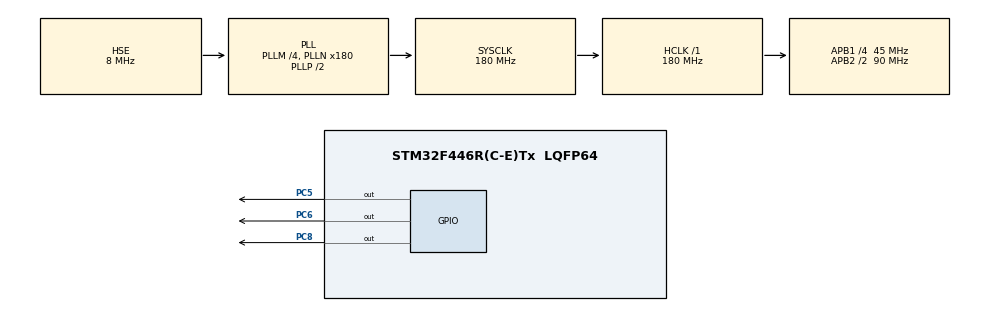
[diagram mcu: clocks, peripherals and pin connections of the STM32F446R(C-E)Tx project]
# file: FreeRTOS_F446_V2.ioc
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Mcu.Family=STM32F4
Mcu.Name=STM32F446R(C-E)Tx
Mcu.Package=LQFP64
NVIC.PriorityGroup=NVIC_PRIORITYGROUP_4
NVIC.TIM8_TRG_COM_TIM14_IRQn=true\:5\:0\:true\:false\:true\:false\:true\:true
NVIC.TimeBase=TIM8_TRG_COM_TIM14_IRQn
NVIC.TimeBaseIP=TIM14
PA13.Mode=Trace_Asynchronous_SW
PA13.Signal=SYS_JTMS-SWDIO
PA14.Mode=Trace_Asynchronous_SW
PA14.Signal=SYS_JTCK-SWCLK
PB3.Mode=Trace_Asynchronous_SW
PB3.Signal=SYS_JTDO-SWO
PC5.Signal=GPIO_Output
PC6.Signal=GPIO_Output
PC8.Signal=GPIO_Output
PH0-OSC_IN.Mode=HSE-External-Clock-Source
PH0-OSC_IN.Signal=RCC_OSC_IN
PH1-OSC_OUT.Mode=HSE-External-Clock-Source
PH1-OSC_OUT.Signal=RCC_OSC_OUT
ProjectManager.HeapSize=0x200
ProjectManager.StackSize=0x400
ProjectManager.TargetToolchain=STM32CubeIDE
RCC.AHBFreq_Value=180000000
RCC.APB1CLKDivider=RCC_HCLK_DIV4
RCC.APB1Freq_Value=45000000
RCC.APB1TimFreq_Value=90000000
RCC.APB2CLKDivider=RCC_HCLK_DIV2
RCC.APB2Freq_Value=90000000
RCC.APB2TimFreq_Value=180000000
RCC.CortexFreq_Value=180000000
RCC.HCLKFreq_Value=180000000
RCC.HSE_VALUE=8000000
RCC.PLLM=4
RCC.PLLN=180
RCC.PLLSourceVirtual=RCC_PLLSOURCE_HSE
RCC.SYSCLKFreq_VALUE=180000000
RCC.SYSCLKSource=RCC_SYSCLKSOURCE_PLLCLK
RCC.USBFreq_Value=180000000
RCC.VCOOutputFreq_Value=360000000
VP_SYS_VS_tim14.Mode=TIM14
board=custom

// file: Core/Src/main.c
/* USER CODE BEGIN Header */
/**
  ******************************************************************************
  * @file           : main.c
  * @brief          : Main program body
  ******************************************************************************
  * @attention
  *
  * Copyright (c) 2025 STMicroelectronics.
  * All rights reserved.
  *
  * This software is licensed under terms that can be found in the LICENSE file
  * in the root directory of this software component.
  * If no LICENSE file comes with this software, it is provided AS-IS.
  *
  ******************************************************************************
  */
/* USER CODE END Header */
#include "main.h"

/* USER CODE BEGIN Includes */
#include"FreeRTOS.h"
#include"task.h"
#include <stdbool.h>

/* USER CODE END Includes */

/* USER CODE BEGIN PD */
#define DWT_CTRL    (*(volatile uint32_t*)0xE0001000)
/* USER CODE END PD */

/* USER CODE BEGIN PV */

TaskHandle_t Task1Handle = NULL;
TaskHandle_t Task2Handle = NULL;
TaskHandle_t Task3Handle = NULL;
TaskHandle_t ButtonTaskHandle = NULL;

TaskHandle_t NumberDeleteTask = NULL;

/* USER CODE END PV */

void SystemClock_Config(void);
static void MX_GPIO_Init(void);

/* USER CODE BEGIN 0 */

extern  void SEGGER_UART_init(uint32_t);

void vTaskCode1( void * pvParameters )
{
	( void ) pvParameters;

	BaseType_t status;

	for( ;; )
	{
		HAL_GPIO_TogglePin(GPIOC, GPIO_PIN_5);
		status = xTaskNotifyWait(0,0,NULL,pdMS_TO_TICKS(200));
		if(status == pdPASS)
		{
			NumberDeleteTask = Task2Handle;
			vTaskDelete(Task1Handle);
		}

	}
}

void vTaskCode2( void * pvParameters )
{
	( void ) pvParameters;

	BaseType_t status;

	for( ;; )
	{
		HAL_GPIO_TogglePin(GPIOC, GPIO_PIN_6);
		status = xTaskNotifyWait(0,0,NULL,pdMS_TO_TICKS(400));
		if(status == pdPASS)
		{
			NumberDeleteTask = Task3Handle;
			vTaskDelete(Task2Handle);
		}
	}
}

void vTaskCode3( void * pvParameters )
{
	( void ) pvParameters;

	BaseType_t status;

	for( ;; )
	{

		HAL_GPIO_TogglePin(GPIOC, GPIO_PIN_8);
		status = xTaskNotifyWait(0,0,NULL,pdMS_TO_TICKS(800));
		if(status == pdPASS)
		{
			vTaskDelete(Task3Handle);
		}
	}
}

void ButtonTask( void * pvParameters )
{
	( void ) pvParameters;
	bool state = 0;
	bool prev_red = 0;
	NumberDeleteTask = Task1Handle;

	for( ;; )
	{
		state = HAL_GPIO_ReadPin(GPIOC, GPIO_PIN_13);
		if(!state)
		{
			if(prev_red)
			{
				xTaskNotify(NumberDeleteTask, 0,eNoAction);
			}
		}
		prev_red = state;

		vTaskDelay( pdMS_TO_TICKS(10) );
	}
}

/* USER CODE END 0 */

int main(void)
{

  /* MCU Configuration--------------------------------------------------------*/

  /* Reset of all peripherals, Initializes the Flash interface and the Systick. */
  HAL_Init();

  /* Configure the system clock */
  SystemClock_Config();

  /* Initialize all configured peripherals */
  MX_GPIO_Init();
  /* USER CODE BEGIN 2 */

  DWT_CTRL |= ( 1 << 0);

  SEGGER_UART_init(500000);

  SEGGER_SYSVIEW_Conf();

  BaseType_t xReturned;

  xReturned = xTaskCreate(
	  vTaskCode1,       // Функция задачи
	  "Task1",          // Имя задачи (для отладки)
	  128,             // Размер стека задачи в словах
	  NULL,   		   // Параметр, передаваемый в задачу
	  1, 				// Приоритет задачи
	  &Task1Handle );          // Указатель на дескриптор задачи (не используется здесь)

  configASSERT(xReturned == pdPASS); // Проверка успешного создания задачи

  xReturned = xTaskCreate(
  	  vTaskCode2,       // Функция задачи
  	  "Task2",          // Имя задачи (для отладки)
  	  128,             // Размер стека задачи в словах
  	  NULL,   		   // Параметр, передаваемый в задачу
  	  2, 				// Приоритет задачи
	  &Task2Handle );          // Указатель на дескриптор задачи (не используется здесь)

  configASSERT(xReturned == pdPASS);

  xReturned = xTaskCreate(
	  vTaskCode3,       // Функция задачи
  	  "Task3",          // Имя задачи (для отладки)
  	  128,             // Размер стека задачи в словах
  	  NULL,   		   // Параметр, передаваемый в задачу
  	  3, 				// Приоритет задачи
	  &Task3Handle );          // Указатель на дескриптор задачи (не используется здесь)

  configASSERT(xReturned == pdPASS);

  xReturned = xTaskCreate(
	  ButtonTask,       // Функция задачи
  	  "Button Task",          // Имя задачи (для отладки)
  	  128,             // Размер стека задачи в словах
  	  NULL,   		   // Параметр, передаваемый в задачу
  	  4, 				// Приоритет задачи
	  &ButtonTaskHandle );          // Указатель на дескриптор задачи (не используется здесь)

  vTaskStartScheduler();

  configASSERT(0);

  /* USER CODE END 2 */

  /* Infinite loop */
  while (1)
  {

  }
}

void SystemClock_Config(void)
{
  RCC_OscInitTypeDef RCC_OscInitStruct = {0};
  RCC_ClkInitTypeDef RCC_ClkInitStruct = {0};

  /** Configure the main internal regulator output voltage
  */
  __HAL_RCC_PWR_CLK_ENABLE();
  __HAL_PWR_VOLTAGESCALING_CONFIG(PWR_REGULATOR_VOLTAGE_SCALE1);

  /** Initializes the RCC Oscillators according to the specified parameters
  * in the RCC_OscInitTypeDef structure.
  */
  RCC_OscInitStruct.OscillatorType = RCC_OSCILLATORTYPE_HSE;
  RCC_OscInitStruct.HSEState = RCC_HSE_BYPASS;
  RCC_OscInitStruct.PLL.PLLState = RCC_PLL_ON;
  RCC_OscInitStruct.PLL.PLLSource = RCC_PLLSOURCE_HSE;
  RCC_OscInitStruct.PLL.PLLM = 4;
  RCC_OscInitStruct.PLL.PLLN = 180;
  RCC_OscInitStruct.PLL.PLLP = RCC_PLLP_DIV2;
  RCC_OscInitStruct.PLL.PLLQ = 2;
  RCC_OscInitStruct.PLL.PLLR = 2;
  if (HAL_RCC_OscConfig(&RCC_OscInitStruct) != HAL_OK)
  {
    Error_Handler();
  }

  /** Activate the Over-Drive mode
  */
  if (HAL_PWREx_EnableOverDrive() != HAL_OK)
  {
    Error_Handler();
  }

  /** Initializes the CPU, AHB and APB buses clocks
  */
  RCC_ClkInitStruct.ClockType = RCC_CLOCKTYPE_HCLK|RCC_CLOCKTYPE_SYSCLK
                              |RCC_CLOCKTYPE_PCLK1|RCC_CLOCKTYPE_PCLK2;
  RCC_ClkInitStruct.SYSCLKSource = RCC_SYSCLKSOURCE_PLLCLK;
  RCC_ClkInitStruct.AHBCLKDivider = RCC_SYSCLK_DIV1;
  RCC_ClkInitStruct.APB1CLKDivider = RCC_HCLK_DIV4;
  RCC_ClkInitStruct.APB2CLKDivider = RCC_HCLK_DIV2;

  if (HAL_RCC_ClockConfig(&RCC_ClkInitStruct, FLASH_LATENCY_5) != HAL_OK)
  {
    Error_Handler();
  }
}

static void MX_GPIO_Init(void)
{
  GPIO_InitTypeDef GPIO_InitStruct = {0};

  /* GPIO Ports Clock Enable */
  __HAL_RCC_GPIOH_CLK_ENABLE();
  __HAL_RCC_GPIOC_CLK_ENABLE();
  __HAL_RCC_GPIOA_CLK_ENABLE();
  __HAL_RCC_GPIOB_CLK_ENABLE();

  /*Configure GPIO pin Output Level */
  HAL_GPIO_WritePin(GPIOC, GPIO_PIN_5|GPIO_PIN_6|GPIO_PIN_8, GPIO_PIN_RESET);

  /*Configure GPIO pins : PC5 PC6 PC8 */
  GPIO_InitStruct.Pin = GPIO_PIN_5|GPIO_PIN_6|GPIO_PIN_8;
  GPIO_InitStruct.Mode = GPIO_MODE_OUTPUT_PP;
  GPIO_InitStruct.Pull = GPIO_NOPULL;
  GPIO_InitStruct.Speed = GPIO_SPEED_FREQ_LOW;
  HAL_GPIO_Init(GPIOC, &GPIO_InitStruct);

}

void HAL_TIM_PeriodElapsedCallback(TIM_HandleTypeDef *htim)
{
  if (htim->Instance == TIM14)
  {
    HAL_IncTick();
  }
}

void Error_Handler(void)
{
  __disable_irq();
  while (1)
  {
  }
}
